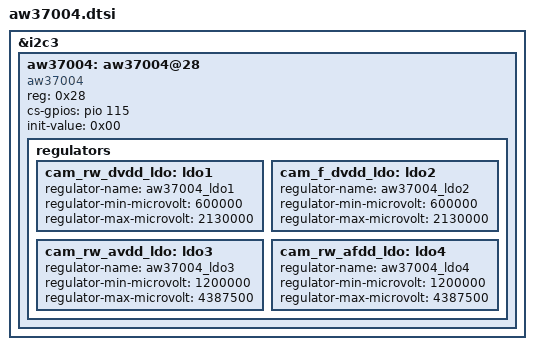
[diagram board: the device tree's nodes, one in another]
&i2c3{
    aw37004: aw37004@28 {
	status = "okay";
	compatible = "aw37004";
	reg = <0x28>;
	cs-gpios = <&pio 115 0>;
	init-value = <0x00>;
    	regulators{
		cam_rw_dvdd_ldo: ldo1 {
			regulator-name = "aw37004_ldo1";
			regulator-min-microvolt = <600000>;
			regulator-max-microvolt = <2130000>;
		};

		cam_f_dvdd_ldo: ldo2 {
			regulator-name = "aw37004_ldo2";
			regulator-min-microvolt = <600000>;
			regulator-max-microvolt = <2130000>;

		};

		cam_rw_avdd_ldo: ldo3 {
			regulator-name = "aw37004_ldo3";
			regulator-min-microvolt = <1200000>;
			regulator-max-microvolt = <4387500>;

		};

		cam_rw_afdd_ldo: ldo4 {
			regulator-name = "aw37004_ldo4";
			regulator-min-microvolt = <1200000>;
			regulator-max-microvolt = <4387500>;

		};
	};
};
};
